VERSION ""

NS_ :

BS_:

BU_: ECU Display

BO_ 1289 Debug9: 5 ECU
 SG_ LogicState_RR : 24|4@1+ (1,0) [0|15] "" Vector__XXX
 SG_ LogicState_RL : 28|4@1+ (1,0) [0|15] "" Vector__XXX
 SG_ LogicState_FR : 32|4@1+ (1,0) [0|15] "" Vector__XXX
 SG_ LogicState_FL : 36|4@1+ (1,0) [0|15] "" Vector__XXX
 SG_ FR_AMK_bEnable : 20|1@1+ (1,0) [0|1] "" Vector__XXX
 SG_ FL_AMK_bEnable : 21|1@1+ (1,0) [0|1] "" Vector__XXX
 SG_ RR_AMK_bEnable : 22|1@1+ (1,0) [0|1] "" Vector__XXX
 SG_ RL_AMK_bEnable : 23|1@1+ (1,0) [0|1] "" Vector__XXX
 SG_ FR_AMK_bQuitInverterOn : 16|1@1+ (1,0) [0|1] "" Vector__XXX
 SG_ FL_AMK_bQuitInverterOn : 17|1@1+ (1,0) [0|1] "" Vector__XXX
 SG_ RR_AMK_bQuitInverterOn : 18|1@1+ (1,0) [0|1] "" Vector__XXX
 SG_ RL_AMK_bQuitInverterOn : 19|1@1+ (1,0) [0|1] "" Vector__XXX
 SG_ FR_AMK_bQuitDcOn : 12|1@1+ (1,0) [0|1] "" Vector__XXX
 SG_ FL_AMK_bQuitDcOn : 13|1@1+ (1,0) [0|1] "" Vector__XXX
 SG_ RR_AMK_bQuitDcOn : 14|1@1+ (1,0) [0|1] "" Vector__XXX
 SG_ RL_AMK_bQuitDcOn : 15|1@1+ (1,0) [0|1] "" Vector__XXX
 SG_ FR_AMK_bSystemReady : 8|1@1+ (1,0) [0|1] "" Vector__XXX
 SG_ FL_AMK_bSystemReady : 9|1@1+ (1,0) [0|1] "" Vector__XXX
 SG_ RR_AMK_bSystemReady : 10|1@1+ (1,0) [0|1] "" Vector__XXX
 SG_ RL_AMK_bSystemReady : 11|1@1+ (1,0) [0|1] "" Vector__XXX
 SG_ FR_AMK_bError : 0|1@1+ (1,0) [0|1] "" Vector__XXX
 SG_ FL_AMK_bError : 1|1@1+ (1,0) [0|1] "" Vector__XXX
 SG_ RR_AMK_bError : 2|1@1+ (1,0) [0|1] "" Vector__XXX
 SG_ RL_AMK_bError : 3|1@1+ (1,0) [0|1] "" Vector__XXX
 SG_ ModeFlag : 4|4@1- (1,0) [-8|7] "" Vector__XXX

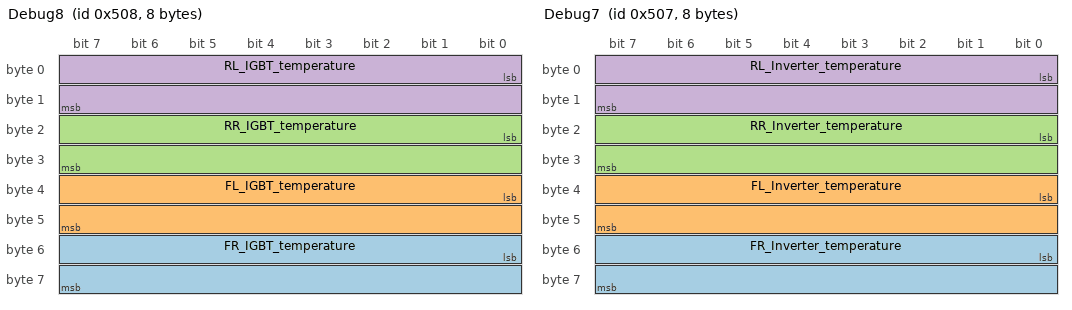
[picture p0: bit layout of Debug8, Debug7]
BO_ 1288 Debug8: 8 ECU
 SG_ FR_IGBT_temperature : 48|16@1- (0.1,0) [-3276.8|3276.7] "°" Vector__XXX
 SG_ FL_IGBT_temperature : 32|16@1- (0.1,0) [-3276.8|3276.7] "°" Vector__XXX
 SG_ RR_IGBT_temperature : 16|16@1- (0.1,0) [-3276.8|3276.7] "°" Vector__XXX
 SG_ RL_IGBT_temperature : 0|16@1- (0.1,0) [-3276.8|3276.7] "°" Vector__XXX

BO_ 1287 Debug7: 8 ECU
 SG_ FR_Inverter_temperature : 48|16@1- (0.1,0) [-3276.8|3276.7] "°" Vector__XXX
 SG_ FL_Inverter_temperature : 32|16@1- (0.1,0) [-3276.8|3276.7] "°" Vector__XXX
 SG_ RR_Inverter_temperature : 16|16@1- (0.1,0) [-3276.8|3276.7] "°" Vector__XXX
 SG_ RL_Inverter_temperature : 0|16@1- (0.1,0) [-3276.8|3276.7] "°" Vector__XXX

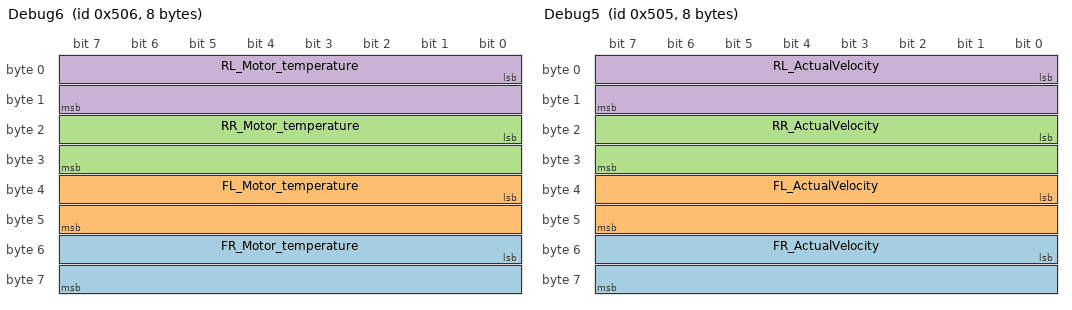
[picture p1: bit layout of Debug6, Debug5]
BO_ 1286 Debug6: 8 ECU
 SG_ FR_Motor_temperature : 48|16@1- (0.1,0) [-3276.8|3276.7] "°" Vector__XXX
 SG_ FL_Motor_temperature : 32|16@1- (0.1,0) [-3276.8|3276.7] "°" Vector__XXX
 SG_ RR_Motor_temperature : 16|16@1- (0.1,0) [-3276.8|3276.7] "°" Vector__XXX
 SG_ RL_Motor_temperature : 0|16@1- (0.1,0) [-3276.8|3276.7] "°" Vector__XXX

BO_ 1285 Debug5: 8 ECU
 SG_ FR_ActualVelocity : 48|16@1- (1,0) [-32768|32767] "" Vector__XXX
 SG_ FL_ActualVelocity : 32|16@1- (1,0) [-32768|32767] "" Vector__XXX
 SG_ RR_ActualVelocity : 16|16@1- (1,0) [-32768|32767] "" Vector__XXX
 SG_ RL_ActualVelocity : 0|16@1- (1,0) [-32768|32767] "" Vector__XXX

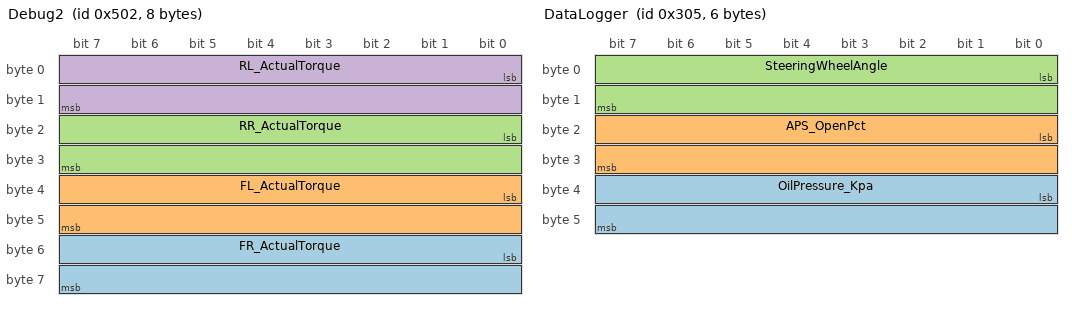
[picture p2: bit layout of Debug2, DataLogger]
BO_ 1282 Debug2: 8 ECU
 SG_ FR_ActualTorque : 48|16@1- (1,0) [-32768|32767] "0.1%Mn" Vector__XXX
 SG_ FL_ActualTorque : 32|16@1- (1,0) [-32768|32767] "0.1%Mn" Vector__XXX
 SG_ RR_ActualTorque : 16|16@1- (1,0) [-32768|32767] "0.1%Mn" Vector__XXX
 SG_ RL_ActualTorque : 0|16@1- (1,0) [-32768|32767] "0.1%Mn" Vector__XXX

BO_ 773 DataLogger: 6 ECU
 SG_ OilPressure_Kpa : 32|16@1+ (0.001,0) [0|65.535] "Kpa" Vector__XXX
 SG_ APS_OpenPct : 16|16@1+ (0.1,0) [0|6553.5] "%" Vector__XXX
 SG_ SteeringWheelAngle : 0|16@1- (0.1,0) [-3276.8|3276.7] "deg" Vector__XXX

BO_ 1284 Debug4: 8 ECU
 SG_ Diagnostic_number_4 : 32|32@1+ (1,0) [0|4294967295] "" Vector__XXX
 SG_ Diagnostic_number_3 : 0|32@1+ (1,0) [0|4294967295] "" Vector__XXX

BO_ 1283 Debug3: 8 ECU
 SG_ Diagnostic_number_2 : 32|32@1+ (1,0) [0|4294967295] "" Vector__XXX
 SG_ Diagnostic_number_1 : 0|32@1+ (1,0) [0|4294967295] "" Vector__XXX

BO_ 769 GPS_Speed: 2 Display
 SG_ GroundSpeed : 0|16@1+ (0.1,0) [0|300] "km/h" Vector__XXX

BO_ 784 DriveMode_Request: 8 Display
 SG_ DriveModeCode : 0|8@1+ (1,0) [48|51] "" ECU

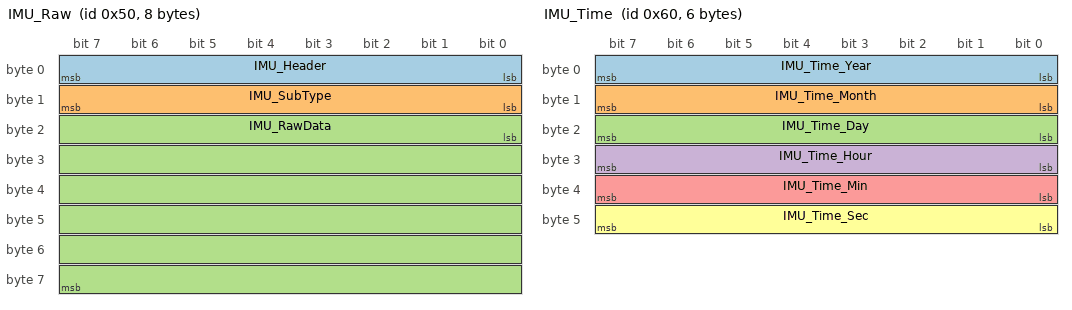
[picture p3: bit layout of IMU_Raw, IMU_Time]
BO_ 80 IMU_Raw: 8 Display
 SG_ IMU_Header : 0|8@1+ (1,0) [85|85] "" Vector__XXX
 SG_ IMU_SubType : 8|8@1+ (1,0) [80|84] "" Vector__XXX
 SG_ IMU_RawData : 16|48@1+ (1,0) [0|281474976710655] "" Vector__XXX

BO_ 96 IMU_Time: 6 Display
 SG_ IMU_Time_Year : 0|8@1+ (1,2000) [0|99] "" Vector__XXX
 SG_ IMU_Time_Month : 8|8@1+ (1,0) [1|12] "" Vector__XXX
 SG_ IMU_Time_Day : 16|8@1+ (1,0) [1|31] "" Vector__XXX
 SG_ IMU_Time_Hour : 24|8@1+ (1,0) [0|23] "" Vector__XXX
 SG_ IMU_Time_Min : 32|8@1+ (1,0) [0|59] "" Vector__XXX
 SG_ IMU_Time_Sec : 40|8@1+ (1,0) [0|59] "" Vector__XXX

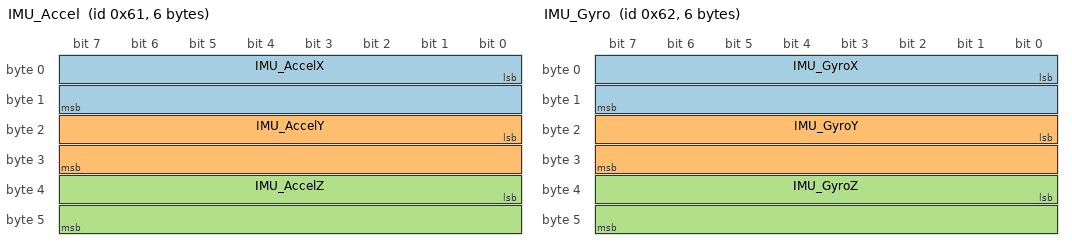
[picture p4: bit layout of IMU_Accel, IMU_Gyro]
BO_ 97 IMU_Accel: 6 Display
 SG_ IMU_AccelX : 0|16@1- (0.00048828125,0) [-16|16] "g" Vector__XXX
 SG_ IMU_AccelY : 16|16@1- (0.00048828125,0) [-16|16] "g" Vector__XXX
 SG_ IMU_AccelZ : 32|16@1- (0.00048828125,0) [-16|16] "g" Vector__XXX

BO_ 98 IMU_Gyro: 6 Display
 SG_ IMU_GyroX : 0|16@1- (0.0610352,0) [-2000|2000] "deg/s" Vector__XXX
 SG_ IMU_GyroY : 16|16@1- (0.0610352,0) [-2000|2000] "deg/s" Vector__XXX
 SG_ IMU_GyroZ : 32|16@1- (0.0610352,0) [-2000|2000] "deg/s" Vector__XXX

BO_ 99 IMU_Roll: 2 Display
 SG_ IMU_Angle_Roll : 0|16@1- (0.005493,0) [-180|180] "deg" Vector__XXX

BO_ 100 IMU_Pitch: 2 Display
 SG_ IMU_Angle_Pitch : 0|16@1- (0.005493,0) [-90|90] "deg" Vector__XXX

BO_ 101 IMU_Yaw: 2 Display
 SG_ IMU_Angle_Yaw : 0|16@1- (0.005493,0) [-180|180] "deg" Vector__XXX

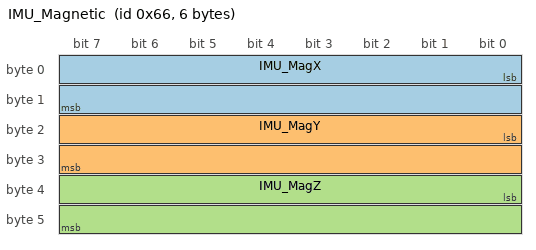
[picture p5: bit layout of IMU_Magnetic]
BO_ 102 IMU_Magnetic: 6 Display
 SG_ IMU_MagX : 0|16@1- (1,0) [-32768|32767] "" Vector__XXX
 SG_ IMU_MagY : 16|16@1- (1,0) [-32768|32767] "" Vector__XXX
 SG_ IMU_MagZ : 32|16@1- (1,0) [-32768|32767] "" Vector__XXX

CM_ SG_ 1289 FR_AMK_bEnable "表示电机是否使能表示电机是否使能表示电机是否使能表示电机是否使能";
CM_ SG_ 1288 FR_IGBT_temperature "锟斤拷位锟斤拷锟斤拷锟较讹拷锟斤拷位锟斤拷锟斤拷锟较讹拷锟斤拷位锟斤拷锟斤拷锟较讹拷锟斤拷位锟斤拷锟斤拷锟较讹拷";
CM_ SG_ 1287 FR_Inverter_temperature "锟斤拷位锟斤拷锟斤拷锟较讹拷锟斤拷位锟斤拷锟斤拷锟较讹拷锟斤拷位锟斤拷锟斤拷锟较讹拷锟斤拷位锟斤拷锟斤拷锟较讹拷";
CM_ SG_ 1286 FR_Motor_temperature "锟斤拷位锟斤拷锟斤拷锟较讹拷锟斤拷位锟斤拷锟斤拷锟较讹拷锟斤拷位锟斤拷锟斤拷锟较讹拷锟斤拷位锟斤拷锟斤拷锟较讹拷";
CM_ SG_ 1282 FR_ActualTorque "左前实际扭矩右前实际扭矩右后实际扭矩左后实际扭矩";
CM_ SG_ 773 OilPressure_Kpa "油压信号，单位是Kpa";
CM_ SG_ 773 APS_OpenPct "0~100%表示油门开度";
CM_ SG_ 773 SteeringWheelAngle "方向盘转角从-137到136deg";
CM_ SG_ 769 GroundSpeed "GPS地速, 分辨率0.1km/h, Display->ECU";
CM_ SG_ 784 DriveModeCode "Drive mode request: 48=S, 49=Q, 50=C, 51=E, Display->ECU";
CM_ SG_ 80 IMU_Header "固定帧头 0x55";
CM_ SG_ 80 IMU_SubType "分包类型: 0x50=时间,0x51=加速度,0x52=角速度,0x53=角度,0x54=磁场";
CM_ SG_ 80 IMU_RawData "随SubType变化的数据载荷, 具体定义见分包报文 0x60~0x66";
CM_ SG_ 96 IMU_Time_Year "年 (2000+), 分包自 0x50 SubType=0x50";
CM_ SG_ 97 IMU_AccelX "X轴加速度 g, 分包自 0x50 SubType=0x51";
CM_ SG_ 98 IMU_GyroX "X轴角速度 deg/s, 分包自 0x50 SubType=0x52";
CM_ SG_ 99 IMU_Angle_Roll "横滚角 deg, 分包自 0x50 SubType=0x53 SubCmd=1";
CM_ SG_ 100 IMU_Angle_Pitch "俯仰角 deg, 分包自 0x50 SubType=0x53 SubCmd=2";
CM_ SG_ 101 IMU_Angle_Yaw "偏航角 deg, 分包自 0x50 SubType=0x53 SubCmd=3";
CM_ SG_ 102 IMU_MagX "X轴磁场原始值, 分包自 0x50 SubType=0x54";
VAL_ 784 DriveModeCode 48 "S" 49 "Q" 50 "C" 51 "E";
BA_DEF_  "BusType" STRING ;
BA_DEF_DEF_  "BusType" "CAN";
